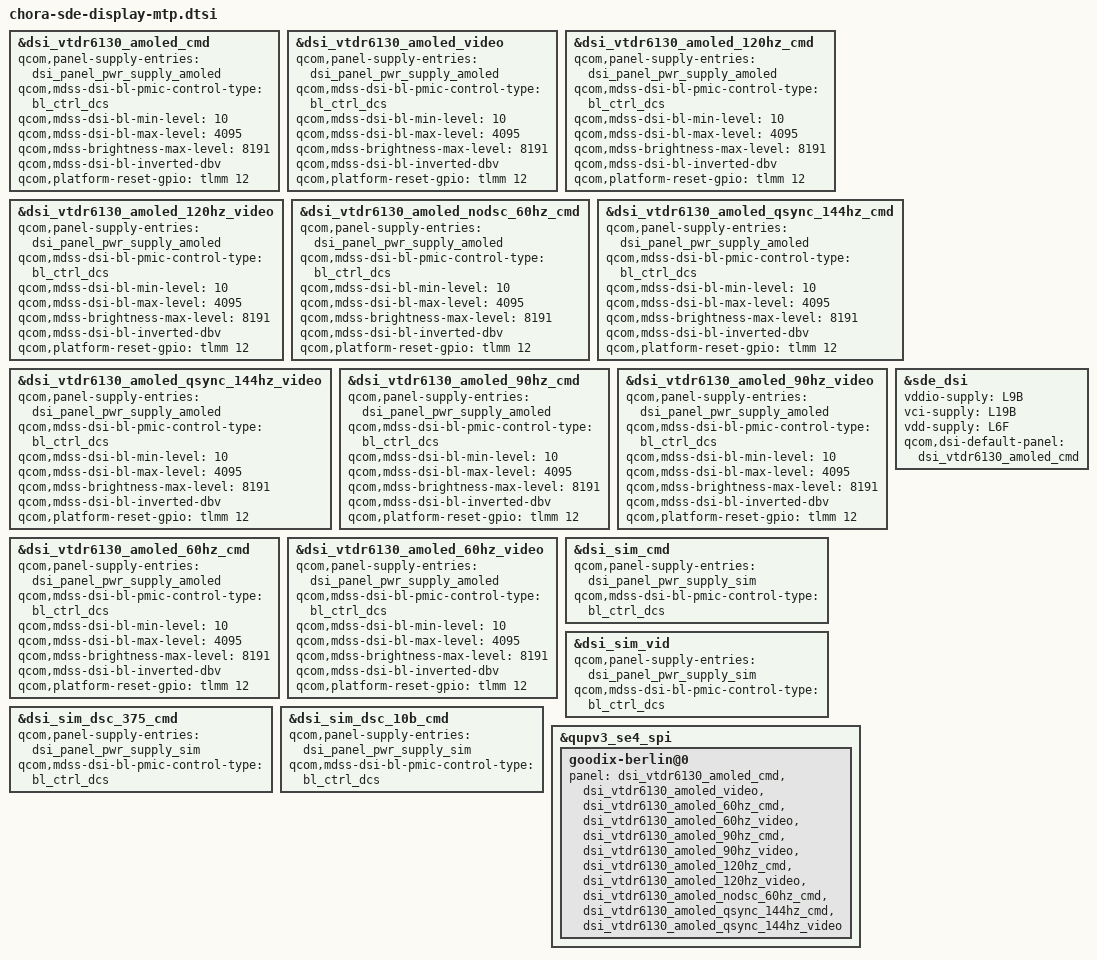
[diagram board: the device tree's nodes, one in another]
// SPDX-License-Identifier: BSD-3-Clause
/*
 * Copyright (c) Qualcomm Technologies, Inc. and/or its subsidiaries.
 */

#include "chora-sde-display.dtsi"

&dsi_vtdr6130_amoled_cmd {
	qcom,panel-supply-entries = <&dsi_panel_pwr_supply_amoled>;
	qcom,mdss-dsi-bl-pmic-control-type = "bl_ctrl_dcs";
	qcom,mdss-dsi-bl-min-level = <10>;
	qcom,mdss-dsi-bl-max-level = <4095>;
	qcom,mdss-brightness-max-level = <8191>;
	qcom,mdss-dsi-bl-inverted-dbv;
	qcom,platform-reset-gpio = <&tlmm 12 0>;
};

&dsi_vtdr6130_amoled_video {
	qcom,panel-supply-entries = <&dsi_panel_pwr_supply_amoled>;
	qcom,mdss-dsi-bl-pmic-control-type = "bl_ctrl_dcs";
	qcom,mdss-dsi-bl-min-level = <10>;
	qcom,mdss-dsi-bl-max-level = <4095>;
	qcom,mdss-brightness-max-level = <8191>;
	qcom,mdss-dsi-bl-inverted-dbv;
	qcom,platform-reset-gpio = <&tlmm 12 0>;
};

&dsi_vtdr6130_amoled_120hz_cmd {
	qcom,panel-supply-entries = <&dsi_panel_pwr_supply_amoled>;
	qcom,mdss-dsi-bl-pmic-control-type = "bl_ctrl_dcs";
	qcom,mdss-dsi-bl-min-level = <10>;
	qcom,mdss-dsi-bl-max-level = <4095>;
	qcom,mdss-brightness-max-level = <8191>;
	qcom,mdss-dsi-bl-inverted-dbv;
	qcom,platform-reset-gpio = <&tlmm 12 0>;
};

&dsi_vtdr6130_amoled_120hz_video {
	qcom,panel-supply-entries = <&dsi_panel_pwr_supply_amoled>;
	qcom,mdss-dsi-bl-pmic-control-type = "bl_ctrl_dcs";
	qcom,mdss-dsi-bl-min-level = <10>;
	qcom,mdss-dsi-bl-max-level = <4095>;
	qcom,mdss-brightness-max-level = <8191>;
	qcom,mdss-dsi-bl-inverted-dbv;
	qcom,platform-reset-gpio = <&tlmm 12 0>;
};

&dsi_vtdr6130_amoled_nodsc_60hz_cmd {
	qcom,panel-supply-entries = <&dsi_panel_pwr_supply_amoled>;
	qcom,mdss-dsi-bl-pmic-control-type = "bl_ctrl_dcs";
	qcom,mdss-dsi-bl-min-level = <10>;
	qcom,mdss-dsi-bl-max-level = <4095>;
	qcom,mdss-brightness-max-level = <8191>;
	qcom,mdss-dsi-bl-inverted-dbv;
	qcom,platform-reset-gpio = <&tlmm 12 0>;
};

&dsi_vtdr6130_amoled_qsync_144hz_cmd {
	qcom,panel-supply-entries = <&dsi_panel_pwr_supply_amoled>;
	qcom,mdss-dsi-bl-pmic-control-type = "bl_ctrl_dcs";
	qcom,mdss-dsi-bl-min-level = <10>;
	qcom,mdss-dsi-bl-max-level = <4095>;
	qcom,mdss-brightness-max-level = <8191>;
	qcom,mdss-dsi-bl-inverted-dbv;
	qcom,platform-reset-gpio = <&tlmm 12 0>;
};

&dsi_vtdr6130_amoled_qsync_144hz_video {
	qcom,panel-supply-entries = <&dsi_panel_pwr_supply_amoled>;
	qcom,mdss-dsi-bl-pmic-control-type = "bl_ctrl_dcs";
	qcom,mdss-dsi-bl-min-level = <10>;
	qcom,mdss-dsi-bl-max-level = <4095>;
	qcom,mdss-brightness-max-level = <8191>;
	qcom,mdss-dsi-bl-inverted-dbv;
	qcom,platform-reset-gpio = <&tlmm 12 0>;
};

&dsi_vtdr6130_amoled_90hz_cmd {
	qcom,panel-supply-entries = <&dsi_panel_pwr_supply_amoled>;
	qcom,mdss-dsi-bl-pmic-control-type = "bl_ctrl_dcs";
	qcom,mdss-dsi-bl-min-level = <10>;
	qcom,mdss-dsi-bl-max-level = <4095>;
	qcom,mdss-brightness-max-level = <8191>;
	qcom,mdss-dsi-bl-inverted-dbv;
	qcom,platform-reset-gpio = <&tlmm 12 0>;
};

&dsi_vtdr6130_amoled_90hz_video {
	qcom,panel-supply-entries = <&dsi_panel_pwr_supply_amoled>;
	qcom,mdss-dsi-bl-pmic-control-type = "bl_ctrl_dcs";
	qcom,mdss-dsi-bl-min-level = <10>;
	qcom,mdss-dsi-bl-max-level = <4095>;
	qcom,mdss-brightness-max-level = <8191>;
	qcom,mdss-dsi-bl-inverted-dbv;
	qcom,platform-reset-gpio = <&tlmm 12 0>;
};

&dsi_vtdr6130_amoled_60hz_cmd {
	qcom,panel-supply-entries = <&dsi_panel_pwr_supply_amoled>;
	qcom,mdss-dsi-bl-pmic-control-type = "bl_ctrl_dcs";
	qcom,mdss-dsi-bl-min-level = <10>;
	qcom,mdss-dsi-bl-max-level = <4095>;
	qcom,mdss-brightness-max-level = <8191>;
	qcom,mdss-dsi-bl-inverted-dbv;
	qcom,platform-reset-gpio = <&tlmm 12 0>;
};

&dsi_vtdr6130_amoled_60hz_video {
	qcom,panel-supply-entries = <&dsi_panel_pwr_supply_amoled>;
	qcom,mdss-dsi-bl-pmic-control-type = "bl_ctrl_dcs";
	qcom,mdss-dsi-bl-min-level = <10>;
	qcom,mdss-dsi-bl-max-level = <4095>;
	qcom,mdss-brightness-max-level = <8191>;
	qcom,mdss-dsi-bl-inverted-dbv;
	qcom,platform-reset-gpio = <&tlmm 12 0>;
};

&dsi_sim_cmd {
	qcom,panel-supply-entries = <&dsi_panel_pwr_supply_sim>;
	qcom,mdss-dsi-bl-pmic-control-type = "bl_ctrl_dcs";
};

&dsi_sim_vid {
	qcom,panel-supply-entries = <&dsi_panel_pwr_supply_sim>;
	qcom,mdss-dsi-bl-pmic-control-type = "bl_ctrl_dcs";
};

&dsi_sim_dsc_375_cmd {
	qcom,panel-supply-entries = <&dsi_panel_pwr_supply_sim>;
	qcom,mdss-dsi-bl-pmic-control-type = "bl_ctrl_dcs";
};

&dsi_sim_dsc_10b_cmd {
	qcom,panel-supply-entries = <&dsi_panel_pwr_supply_sim>;
	qcom,mdss-dsi-bl-pmic-control-type = "bl_ctrl_dcs";
};

&sde_dsi {
	vddio-supply = <&L9B>;
	vci-supply = <&L19B>;
	vdd-supply = <&L6F>;
	qcom,dsi-default-panel = <&dsi_vtdr6130_amoled_cmd>;
};

&qupv3_se4_spi {
	goodix-berlin@0 {
		panel = <&dsi_vtdr6130_amoled_cmd
			&dsi_vtdr6130_amoled_video
			&dsi_vtdr6130_amoled_60hz_cmd
			&dsi_vtdr6130_amoled_60hz_video
			&dsi_vtdr6130_amoled_90hz_cmd
			&dsi_vtdr6130_amoled_90hz_video
			&dsi_vtdr6130_amoled_120hz_cmd
			&dsi_vtdr6130_amoled_120hz_video
			&dsi_vtdr6130_amoled_nodsc_60hz_cmd
			&dsi_vtdr6130_amoled_qsync_144hz_cmd
			&dsi_vtdr6130_amoled_qsync_144hz_video>;
	};
};
